# STM32WB35CCU6A register map
File version: 1.0
Registers are 32-bit, access not given, reset 0x0 unless marked. A register's access mark holds for its fields unless they carry their own. Offsets are from the block's base; [hi:lo] are bit positions; {n}, {i} and the like mark numbered series.

## PWR
Base 0x58000400
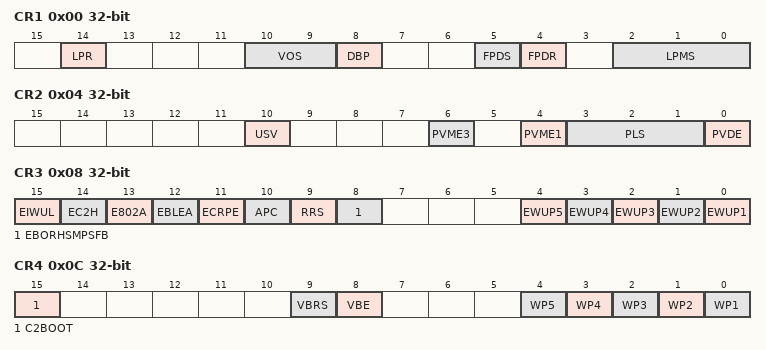
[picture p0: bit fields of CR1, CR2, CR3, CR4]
0x00 CR1
  [14] LPR, [10:9] VOS, [8] DBP, [5] FPDS, [4] FPDR, [2:0] LPMS
0x04 CR2
  [10] USV, [6] PVME3, [4] PVME1, [3:1] PLS, [0] PVDE
0x08 CR3
  [15] EIWUL, [14] EC2H, [13] E802A, [12] EBLEA, [11] ECRPE, [10] APC, [9] RRS, [8] EBORHSMPSFB, [n-1] EWUP{n} (n=1..5)
0x0C CR4
  [15] C2BOOT, [9] VBRS, [8] VBE, [n-1] WP{n} (n=1..5)
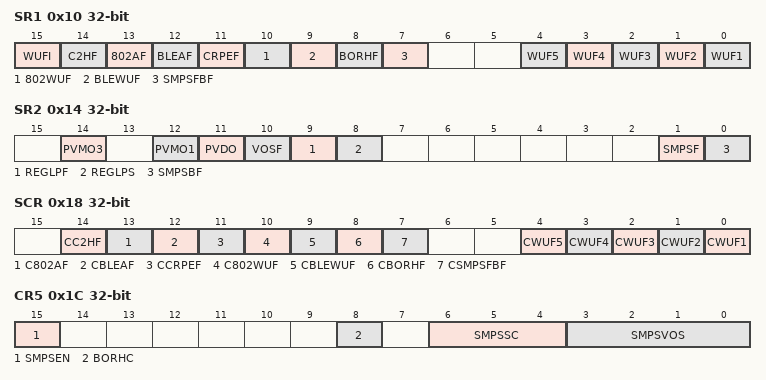
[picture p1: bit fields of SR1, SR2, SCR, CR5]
0x10 SR1
  [15] WUFI, [14] C2HF, [13] 802AF, [12] BLEAF, [11] CRPEF, [10] 802WUF, [9] BLEWUF, [8] BORHF, [7] SMPSFBF, [n-1] WUF{n} (n=1..5)
0x14 SR2
  [14] PVMO3, [12] PVMO1, [11] PVDO, [10] VOSF, [9] REGLPF, [8] REGLPS, [1] SMPSF, [0] SMPSBF
0x18 SCR
  [14] CC2HF, [13] C802AF, [12] CBLEAF, [11] CCRPEF, [10] C802WUF, [9] CBLEWUF, [8] CBORHF, [7] CSMPSFBF, [n-1] CWUF{n} (n=1..5)
0x1C CR5
  [15] SMPSEN, [8] BORHC, [6:4] SMPSSC, [3:0] SMPSVOS
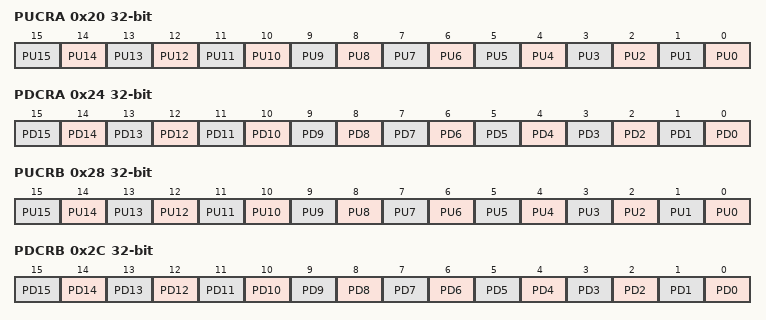
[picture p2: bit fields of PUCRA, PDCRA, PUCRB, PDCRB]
0x20 PUCRA
  [n] PU{n} (n=0..15)
0x24 PDCRA
  [n] PD{n} (n=0..15)
0x28 PUCRB
  [n] PU{n} (n=0..15)
0x2C PDCRB
  [n] PD{n} (n=0..15)
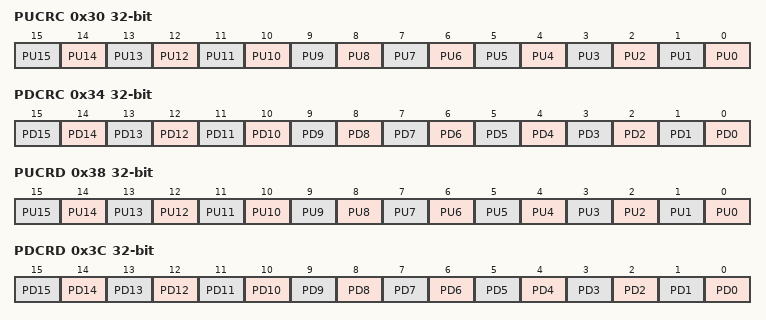
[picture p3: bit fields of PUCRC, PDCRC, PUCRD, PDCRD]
0x30 PUCRC
  [n] PU{n} (n=0..15)
0x34 PDCRC
  [n] PD{n} (n=0..15)
0x38 PUCRD
  [n] PU{n} (n=0..15)
0x3C PDCRD
  [n] PD{n} (n=0..15)
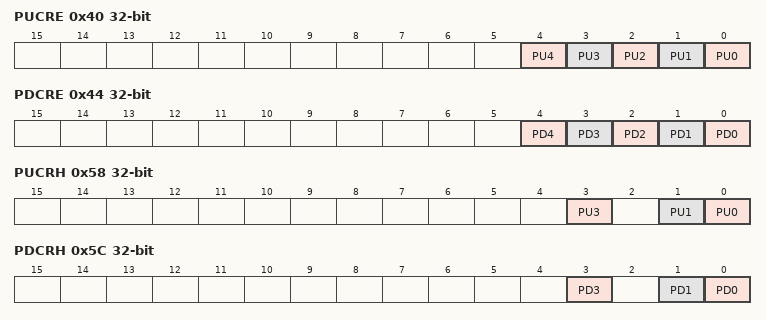
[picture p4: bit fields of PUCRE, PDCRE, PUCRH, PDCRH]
0x40 PUCRE
  [n] PU{n} (n=0..4)
0x44 PDCRE
  [n] PD{n} (n=0..4)
0x58 PUCRH
  [3] PU3, [1] PU1, [0] PU0
0x5C PDCRH
  [3] PD3, [1] PD1, [0] PD0
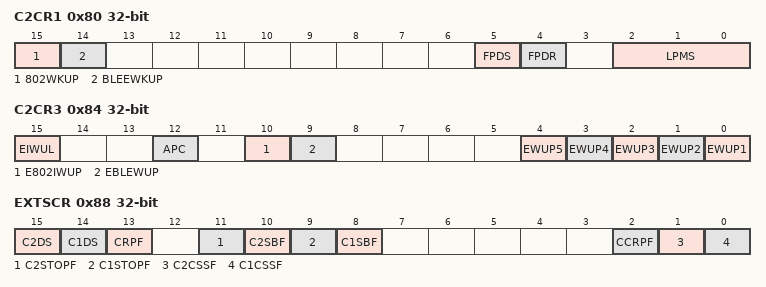
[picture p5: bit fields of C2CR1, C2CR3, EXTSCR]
0x80 C2CR1
  [15] 802WKUP, [14] BLEEWKUP, [5] FPDS, [4] FPDR, [2:0] LPMS
0x84 C2CR3
  [15] EIWUL, [12] APC, [10] E802IWUP, [9] EBLEWUP, [n-1] EWUP{n} (n=1..5)
0x88 EXTSCR
  [15] C2DS, [14] C1DS, [13] CRPF, [11] C2STOPF, [10] C2SBF, [9] C1STOPF, [8] C1SBF, [2] CCRPF, [1] C2CSSF, [0] C1CSSF

## EXTI
Base 0x58000800
0x00 RTSR1
  [31:0] RT
0x04 FTSR1
  [31:0] FT
0x08 SWIER1
  [31:0] SWI
0x0C PR1
  [31:0] PIF
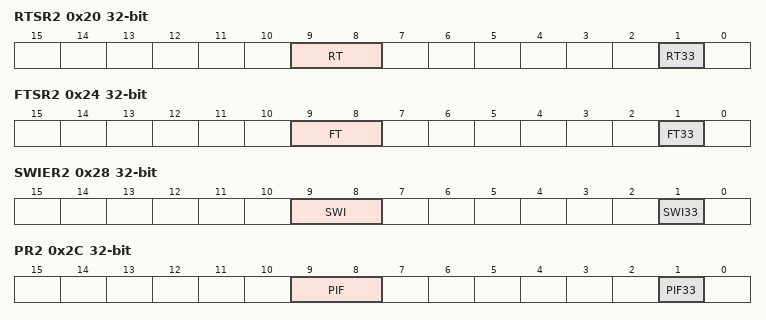
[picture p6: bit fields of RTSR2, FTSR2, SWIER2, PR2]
0x20 RTSR2
  [9:8] RT, [1] RT33
0x24 FTSR2
  [9:8] FT, [1] FT33
0x28 SWIER2
  [9:8] SWI, [1] SWI33
0x2C PR2
  [9:8] PIF, [1] PIF33
0x80 IMR1
  [31:0] IM
0x84 EMR1
  [21:0] EM
0x90 IMR2
  [16:0] IM
0x94 EMR2
  [9:8] EM
0xC0 C2IMR1
  [31:0] IM
0xC4 C2EMR1
  [21:0] EM
0xD0 C2IMR2
  [16:0] IM
0xD4 C2EMR2
  [9:8] EM

## IPCC
Base 0x58000C00
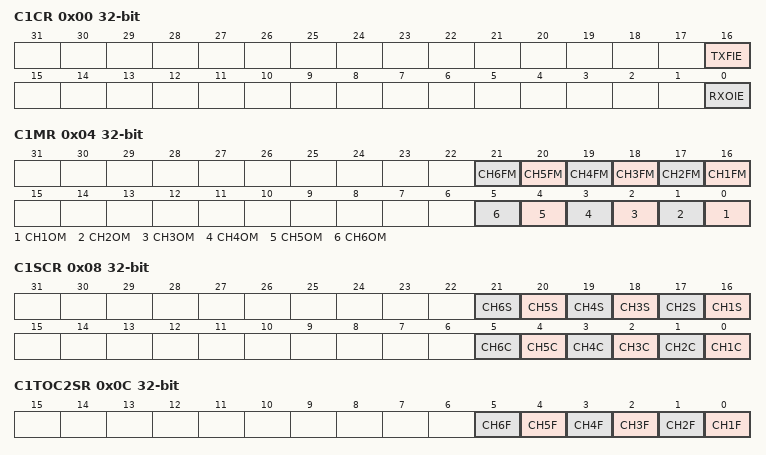
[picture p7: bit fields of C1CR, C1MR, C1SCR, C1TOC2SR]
0x00 C1CR
  [16] TXFIE, [0] RXOIE
0x04 C1MR
  [n+15] CH{n}FM (n=1..6), [n-1] CH{n}OM (n=1..6)
0x08 C1SCR
  [n+15] CH{n}S (n=1..6), [n-1] CH{n}C (n=1..6)
0x0C C1TOC2SR
  [n-1] CH{n}F (n=1..6)
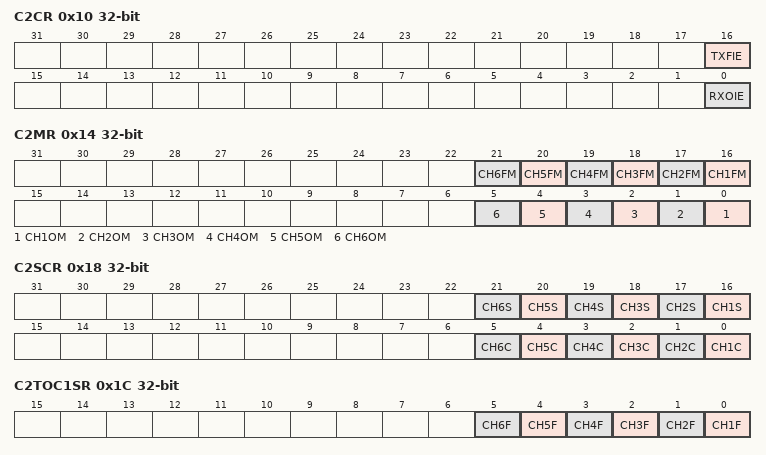
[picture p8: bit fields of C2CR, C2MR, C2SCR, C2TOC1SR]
0x10 C2CR
  [16] TXFIE, [0] RXOIE
0x14 C2MR
  [n+15] CH{n}FM (n=1..6), [n-1] CH{n}OM (n=1..6)
0x18 C2SCR
  [n+15] CH{n}S (n=1..6), [n-1] CH{n}C (n=1..6)
0x1C C2TOC1SR
  [n-1] CH{n}F (n=1..6)

## TRNG
Base 0x58001000
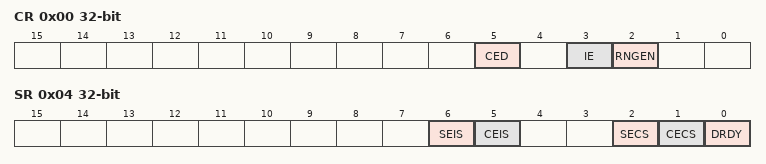
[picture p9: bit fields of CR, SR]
0x00 CR
  [5] CED, [3] IE, [2] RNGEN
0x04 SR
  [6] SEIS, [5] CEIS, [2] SECS, [1] CECS, [0] DRDY
0x08 DR
  [31:0] RNDATA

## HSEM
Base 0x58001400
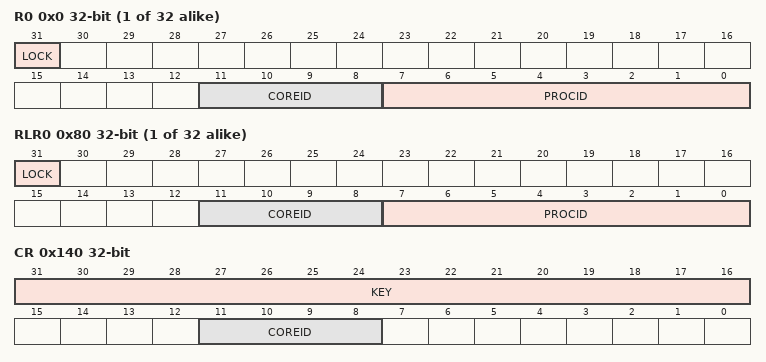
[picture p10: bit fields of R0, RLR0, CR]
{0x0+4i} R{i} (i=0..31)
  [31] LOCK, [11:8] COREID, [7:0] PROCID
{0x80+4i} RLR{i} (i=0..31)
  [31] LOCK, [11:8] COREID, [7:0] PROCID
0x100 C1IER
  [31:0] ISE
0x104 C1ICR
  [31:0] ISC
0x108 C1ISR
  [31:0] ISF
0x10C C1MISR
  [31:0] MISF
0x110 C2IER
  [31:0] ISE
0x114 C2ICR
  [31:0] ISC
0x118 C2ISR
  [31:0] ISF
0x11C C2MISR
  [31:0] MISF
0x140 CR
  [31:16] KEY, [11:8] COREID
0x144 KEYR
  [31:16] KEY

## PKA
Base 0x58002000
Same registers: PKARAM 0x58002400
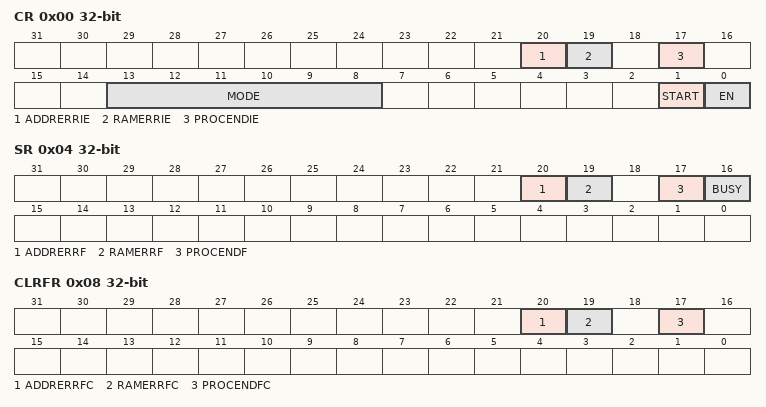
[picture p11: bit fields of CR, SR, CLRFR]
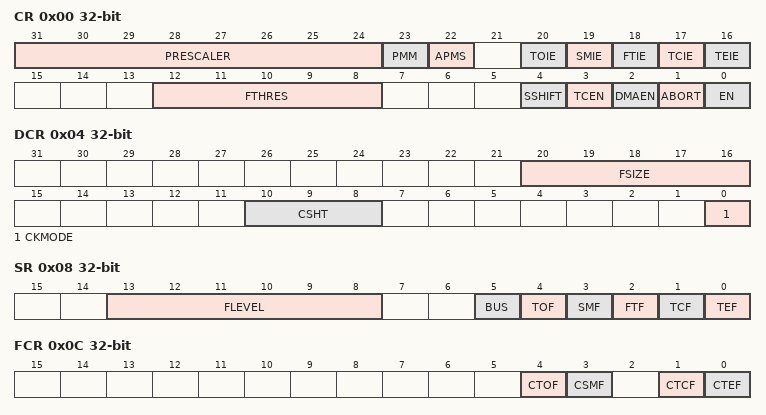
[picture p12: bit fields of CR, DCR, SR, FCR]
0x00 CR
  [20] ADDRERRIE, [19] RAMERRIE, [17] PROCENDIE, [13:8] MODE, [1] START, [0] EN
0x04 SR
  [20] ADDRERRF, [19] RAMERRF, [17] PROCENDF, [16] BUSY
0x08 CLRFR
  [20] ADDRERRFC, [19] RAMERRFC, [17] PROCENDFC

## QUADSPI
Base 0xA0001000
0x00 CR
  [31:24] PRESCALER, [23] PMM, [22] APMS, [20] TOIE, [19] SMIE, [18] FTIE, [17] TCIE, [16] TEIE, [12:8] FTHRES, [4] SSHIFT, [3] TCEN, [2] DMAEN, [1] ABORT, [0] EN
0x04 DCR
  [20:16] FSIZE, [10:8] CSHT, [0] CKMODE
0x08 SR
  [13:8] FLEVEL, [5] BUS, [4] TOF, [3] SMF, [2] FTF, [1] TCF, [0] TEF
0x0C FCR
  [4] CTOF, [3] CSMF, [1] CTCF, [0] CTEF
0x10 DLR
  [31:0] DL
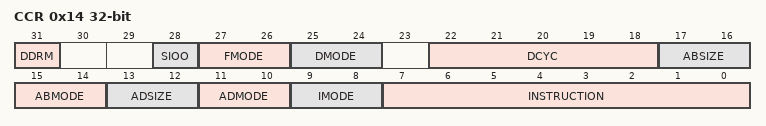
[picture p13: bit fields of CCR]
0x14 CCR
  [31] DDRM, [28] SIOO, [27:26] FMODE, [25:24] DMODE, [22:18] DCYC, [17:16] ABSIZE, [15:14] ABMODE, [13:12] ADSIZE, [11:10] ADMODE, [9:8] IMODE, [7:0] INSTRUCTION
0x18 AR
  [31:0] ADDRESS
0x1C ABR
  [31:0] ALTERNATE
0x20 DR
  [31:0] DATA
0x24 PSMKR
  [31:0] MASK
0x28 PSMAR
  [31:0] MATCH
0x2C PIR
  [15:0] INTERVAL
0x30 LPTR
  [15:0] TIMEOUT
